# ecd5_target_db register map
Vendor: Texas Instruments
Address unit: 16 bits
Registers are 32-bit, access per field, reset 0x0 unless marked. A register's access mark holds for its fields unless they carry their own. Offsets are as the file gives them; [hi:lo] are bit positions; {n}, {i} and the like mark numbered series; 'fields as' and 'values as' point back to an identical list; <NAME> marks a mode.

## DSS (part 3 of 5) — ipxact12_to_ccs_generated
0x324 __ALL___DDR_BITSTRM_BASE_ADDR_SHADOW ro — DDR bitstream base address shadow
  [31:0] ADDR — Shadow base address of bit stream buffer in DDR
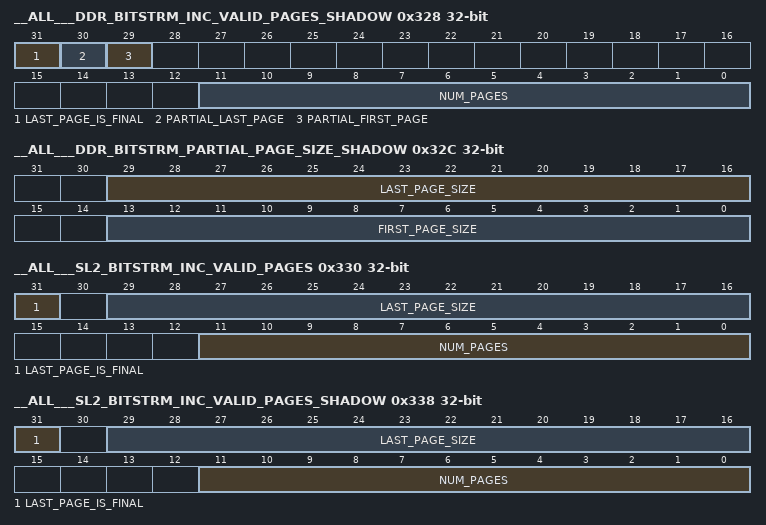
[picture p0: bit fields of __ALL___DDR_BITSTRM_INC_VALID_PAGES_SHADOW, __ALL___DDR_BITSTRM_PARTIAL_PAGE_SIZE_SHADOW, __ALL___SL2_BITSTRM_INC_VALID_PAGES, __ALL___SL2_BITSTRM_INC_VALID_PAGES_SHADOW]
0x328 __ALL___DDR_BITSTRM_INC_VALID_PAGES_SHADOW — DDR bitstream incremental valid pages shadow
  [31] LAST_PAGE_IS_FINAL rw — Shadow of flag indicating whether the last page in the current DDR data descriptor is the last in the DDR, i.e. no more data available in DDR after the last page in the current DDR data descriptor.
  [30] PARTIAL_LAST_PAGE rw — Shadow of flag indicating whether the last page in the current DDR data descriptor is a partial page, i.e. it is not of the full page size.
  [29] PARTIAL_FIRST_PAGE rw — Shadow of flag indicating whether the first page in the current DDR data descriptor is a partial page, i.e. it is not of the full page size. Note : This field is ignored if NUM_PAGES == 1 and PARTIAL_LAST_PAGE == 1.
  [11:0] NUM_PAGES rw — Shadow of the number of bitstream buffer pages that have been incrementally filled in DDR. This is also a working register field and gets decremented after completion of DMA transfer of each page between DDR and SL2
0x32C __ALL___DDR_BITSTRM_PARTIAL_PAGE_SIZE_SHADOW — DDR bitstream incremental valid pages shadow
  [29:16] LAST_PAGE_SIZE rw — Shadow of the size in bytes of the data in the last page. This field is valid only if the DDR_BITSTRM_INC_VALID_PAGES_SHADOW.PARTIAL_LAST_PAGE == 1
  [13:0] FIRST_PAGE_SIZE rw — Shadow of the size in bytes of the data in the last page. This field is valid only if the DDR_BITSTRM_INC_VALID_PAGES_SHADOW.PARTIAL_FIRST_PAGE == 1
0x330 __ALL___SL2_BITSTRM_INC_VALID_PAGES — SL2 bitstream incremental valid pages This register is used only in the fragmented mode
  [31] LAST_PAGE_IS_FINAL rw — Flag indicating whether the last page in the current SL2 data descriptor is the last available i.e. no more data available in SL2 after the last page in the current SL2 data descriptor
  [29:16] LAST_PAGE_SIZE rw — Indicates the size in bytes of the data in the last page. This field is valid only if LAST_PAGE_IS_FINAL == 1
  [11:0] NUM_PAGES rw — Number of bitstream buffer pages that have been incrementally filled in SL2 (in decode), or is available to be filled by the core (in encode)
0x334 __ALL___SL2_BITSTRM_SHADOW_STATUS ro — SL2 bitstream shadow status register This register is used only in the fragmented mode
  [0] INC_VALID_PAGES_UPDATED — Indicates if SL2_BITSTRM_INC_VALID_PAGES contents have been updated 1 : SL2_BITSTRM_INC_VALID_PAGES has been updated and contents have not yet been copied into the shadow register 0 : SL2_BITSTRM_INC_VALID_PAGES has not been updated, or contents have already been copied into the shadow register; SL2_BITSTRM_INC_VALID_PAGES can be written again
0x338 __ALL___SL2_BITSTRM_INC_VALID_PAGES_SHADOW ro — SL2 bitstream incremental valid pages shadow This register is used only in the fragmented mode
  [31] LAST_PAGE_IS_FINAL — Shadow of flag indicating whether the last page in the current SL2 data descriptor is the last available, i.e. no more data available in SL2 after the last page in the current SL2 data descriptor
  [29:16] LAST_PAGE_SIZE — Shadow of the size in bytes of the data in the last page. This field is valid only if LAST_PAGE_IS_FINAL == 1
  [11:0] NUM_PAGES — Shadow number of bitstream buffer pages that have been filled in SL2 (in decode), or available to be filled by the core (in encode); this field gets decremented after ECD5 (SBC) completes processing one page of bit-stream data
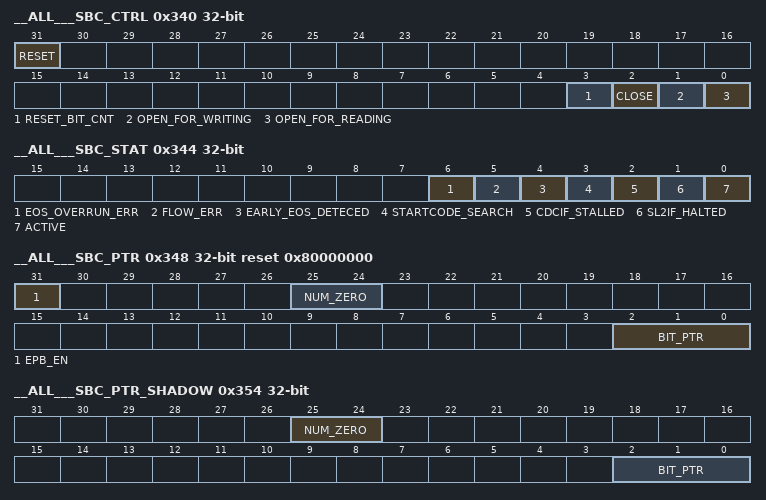
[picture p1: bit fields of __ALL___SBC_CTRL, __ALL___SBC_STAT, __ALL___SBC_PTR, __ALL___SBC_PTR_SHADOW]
0x340 __ALL___SBC_CTRL — SBC Control
  [31] RESET rw — Writing "1" resets SBC; for debug only
  [3] RESET_BIT_CNT rw — Writing "1" resets the bit counters in SBC; resets SBC_TOTAL_COUNT to 0; also resets internal counters; cleared in the next cycle.
  [2] CLOSE rw — Writing "1" closes SBC; automatically cleared on close completion
  [1] OPEN_FOR_WRITING rw — Writing "1" opens SBC for writing; automatically cleared on open completion
  [0] OPEN_FOR_READING rw — Writing "1" opens SBC for reading; automatically cleared on open completion
0x344 __ALL___SBC_STAT ro — SBC Status
  [6] EOS_OVERRUN_ERR — If 1, in decode, indicates that end of slice overrun happened; cleared on open completion.
  [5] FLOW_ERR — If 1, indicates that an underflow (decode) or overflow (encode) error is seen; cleared on open completion.
  [4] EARLY_EOS_DETECED — If 1, in decode, indicates that an early EOS was detected; cleared on open completion.
  [3] STARTCODE_SEARCH — If 1, indicates that startcode search is active; cleared automatically on startcode search completion.
  [2] CDCIF_STALLED — If 1, indicates that codec i/f of SBC is stalled (not ready), due to lack of data in the internal registers of the SBC; valid after open; cleared on codec i/f becoming unstalled.
  [1] SL2IF_HALTED — If 1, indicates that the SL2 i/f of SBC is halted, due to lack of bitstream data in the SL2; valid after open; cleared when SL2 i/f is unhalted
  [0] ACTIVE — If 1, indicates that SBC is active - can be in read/write or halted state; valid after open; cleared on close
0x348 __ALL___SBC_PTR reset 0x80000000 — SL2 bit pointer for SBC
  [31] EPB_EN rw — Enable EPB insertion (encode/write mode) or removal (decode/read mode)
  [25:24] NUM_ZERO rw — Number of zero bytes in the past. This is used for emulation prevention byte manipulation. The following constraint applies : 0 <= NUM_ZERO <= 2
  [2:0] BIT_PTR rw — Next bit position in the byte at BYTEPTR. The following constraint applies : 0 <= BITPTR <= 7
0x34C __ALL___SBC_TOTAL_COUNT — Number of bits read/written by the SBC - i.e. decoded/encoded by the codec
  [26:0] CNT rw — a. In decode, used to keep track of slice level bits decoded b. Additionally, in decode, if SBC_NALU_CFG.SIZE_CHK_EN==1, used to compare against the NALU size to detect bitstream underflow and early EOS c. In encode, used to keep track of slice level bits encoded d. Additionally, in H.241 encode, used to compare against the NALU_CFG.SIZE register to identify slice threshold exceeded condition, and thereby trigger rewind This counter is also incremented during start code searching. This bit count includes EPB. This register will have to be programmed before ECD is triggered for unit processing, to account for the bits decoded/encoded by iCont during header processing
0x350 __ALL___SBC_NALU_CFG — Total size of NALU in bytes
  [21:0] SIZE rw — In decode, specifies the total size of the NALU in bytes. This field is valid/used only if SIZE_CHK_EN == 1. In encode, in H.241 mode, specifies the slice limit
0x354 __ALL___SBC_PTR_SHADOW — SL2 bit pointer shadow for SBC
  [25:24] NUM_ZERO rw — Number of zero bytes in the past. This is used for emulation prevention byte manipulation. The following constraint applies : 0 <= NUM_ZERO <= 2
  [2:0] BIT_PTR rw — Next bit position in the byte at BYTEPTR. The following constraint applies : 0 <= BITPTR <= 7
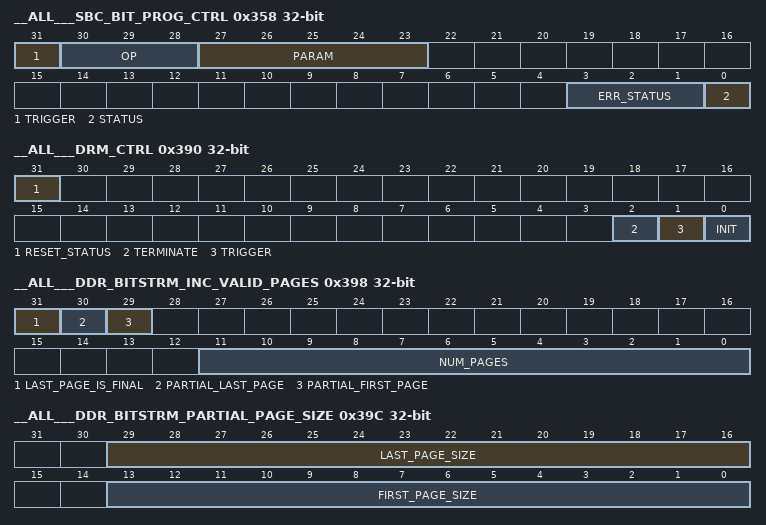
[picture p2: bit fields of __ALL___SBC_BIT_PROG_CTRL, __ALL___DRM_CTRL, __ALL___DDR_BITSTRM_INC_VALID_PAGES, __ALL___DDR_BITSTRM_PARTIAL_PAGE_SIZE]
0x358 __ALL___SBC_BIT_PROG_CTRL — SBC Bit Programmation Control Register
  [31] TRIGGER rw — Writing to this bit triggers the bit processing operation of the SBC. The operation performed depends on the "OP" field. This bit remains set until the specified operation completes, successfully or unsuccessfully
  [30:28] OP rw — Specified the bit manipulation operation to be performed 0x0 : Put bits; write specified (number and value) bits into SL2; increments bit pointer 0x1 : Jump bits; skip over specified number of bits in the SL2; increments the bit pointer 0x2 : Startcode search : do startcode search 0x3 : Get_num_bits_left_in_byte : get the number of bits needed to align the bit pointer to the beginning of the next byte 0x4 : Insert rbsp_trailing_bits; increments bit pointer
  [27:23] PARAM rw — Specifies the parametes for the requested bit processing operation. The meaning of this field depends on the operation requested. The mapping of the operation (OP field) to the meaning of this field is as follows: 0x0 (put bits) : number of bits to be put 0x1 (jump bits) : number of bits to be jumped over; the next 32 bits are then provided in SBC_BIT_PROG_DATA Valid values of this field are 0 to 31
  [3:1] ERR_STATUS rw — If STATUS == 0 when TRIGGER goes to 0, i.e. error was encountered during the specified operation, this field gives details on the error 0x0 : No error 0x1 : SBC not activated yet ( i.e. not opened) 0x2 : If OP == 0 or 1 or 4, SBC not ready; this happens when there is not sufficient bits (in case of decode) or space (in case of encode) to service the specified put_bits or jump_bits request If OP == 2, startcode was not found in the available data, 0x3 : If OP == 2, invalid operation due to startcode search triggered while the SBC was in write mode If OP == 4, invalid operation due to insertion of rbsp_trailing_bits triggered while the SBC was in read mode
  [0] STATUS rw — Indicates the completion status of the specified operation. This field is valid only when "TRIGGER" is 0. This field is cleared on setting TRIGGER to 1. A "1" in this field when TRIGGER goes to 0, indicates successful completion of the specified operation
0x35C __ALL___SBC_BIT_PROG_DATA rw — SBC Bit Programmation Data Register
  [31:0] DATA — If SBC_BIT_PROG_CTRL.OP == 0 (put bits), this register holds the data that needs to be written to SL2 through SBC If SBC_BIT_PROG_CTRL.OP == 1 (jump bits), this register holds the next 32 bit data read from SL2 through SBC, after jumping by the specified length If SBC_BIT_PROG_CTRL.OP == 3 (get bits left in byte), this register holds the number of bits left in the current byte, to align to the next byte boundary
0x390 __ALL___DRM_CTRL — DRM Control for bitstream
  [31] RESET_STATUS rw — Reset the status bits in DDR_BITSTRM_SHADOW_STATUS and SL2_BITSTRM_SHADOW_STATUS; Cleared in the next cycle
  [2] TERMINATE rw — Debug only. Terminate DMA transfers; if set, then the following actions take place - All in-flight DMA is completed - If DMA direction is from SL2 to DDR, all pending DMA requests are completed - If DMA direction is from DDR to SL2, all pending DMA requests are discarded. - Status bits in DDR_BITSTRM_SHADOW_STATUS register are reset
  [1] TRIGGER rw — Debug only. SW trigger; used to indicate consumption on 1 page in the buffer. Setting this bit will trigger a VDMA request.
  [0] INIT rw — Initializes the bitstream DRM FSM. This bit can be set to start the bit stream DMA through SW programming only, without involving the ECD5 controller logic.
0x394 __ALL___DDR_BITSTRM_BASE_ADDR rw — DDR bitstream base address
  [31:0] DDR_BITSTRM_BASE_ADDR — Base address of bit stream buffer in DDR
0x398 __ALL___DDR_BITSTRM_INC_VALID_PAGES — DDR bitstream incremental valid pages
  [31] LAST_PAGE_IS_FINAL rw — Flag indicating whether the last page in the current DDR data descriptor is the last in the DDR, i.e. no more data available in DDR after the last page in the current DDR data descriptor. The DRM's VDMA i/f will terminate after the transfer of the last page in the current descriptor, if this flag is set. Any descriptors already programmed after the current descriptor will remain unused.
  [30] PARTIAL_LAST_PAGE rw — Flag indicating whether the last page in the current DDR data descriptor is a partial page, i.e. it is not of the full page size. The size of the partial page is specified in DDR_BITSTRM_PARTIAL_PAGE_SIZE.LAST_PAGE_SIZE. Data transferred to/from the SL2 will be aligned to the top of the SL2 page, i.e. DDR_BITSTRM_PARTIAL_PAGE_SIZE.LAST_PAGE_SIZE amount of data will be transferred to/from the top of the current SL2 page.
  [29] PARTIAL_FIRST_PAGE rw — Flag indicating whether the first page in the current DDR data descriptor is a partial page, i.e. it is not of the full page size. The size of the partial page is specified in DDR_BITSTRM_PARTIAL_PAGE_SIZE.FIRST_PAGE_SIZE. Data transferred to/from the SL2 will be aligned to the bottom of the SL2 page, i.e. DDR_BITSTRM_PARTIAL_PAGE_SIZE.FIRST_PAGE_SIZE amount of data will be transferred to/from the bottom of the current SL2 page. Note : This field is ignored if NUM_PAGES == 1 and PARTIAL_LAST_PAGE == 1.
  [11:0] NUM_PAGES rw — Number of bitstream buffer pages that have been incrementally filled in DDR. Setting this field to 0 force terminates the DRM's VDMA i/f (forces DRM VDMA i/f FSM to IDLE state, clears the fields of DDR_BITSTRM_SHADOW_STATUS) after completion of all previous data transfers specified by any previous bit stream descriptor. If there are no data transfers pending, setting this field to 0 force terminates the DRM immediately. Additionally, setting this bit causes the DRM to signal the last page of the previous bitstream descriptor as last, to the SBC. Note : If PARTIAL_FIRST_PAGE == PARTIAL_LAST_PAGE == 1, then NUM_PAGES has to be greater than 2.
0x39C __ALL___DDR_BITSTRM_PARTIAL_PAGE_SIZE — DDR bitstream incremental valid pages
  [29:16] LAST_PAGE_SIZE rw — Indicates the size in bytes of the data in the last page. This field is valid only if the DDR_BITSTRM_INC_VALID_PAGES.PARTIAL_LAST_PAGE == 1
  [13:0] FIRST_PAGE_SIZE rw — Indicates the size in bytes of the data in the last page. This field is valid only if the DDR_BITSTRM_INC_VALID_PAGES.PARTIAL_FIRST_PAGE == 1
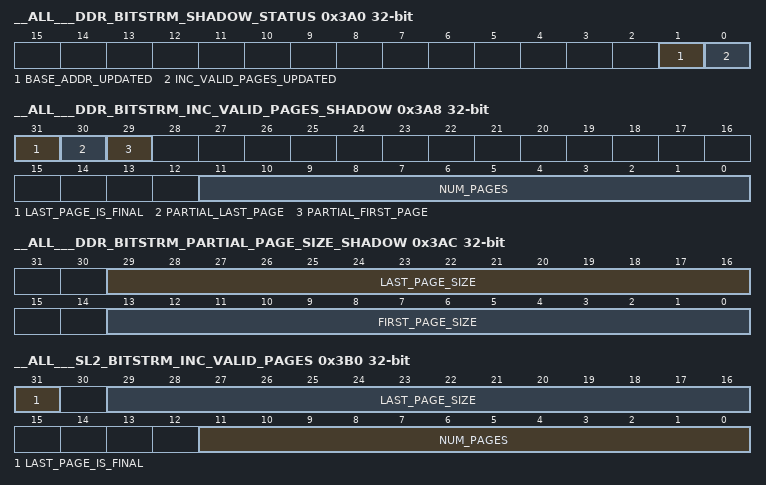
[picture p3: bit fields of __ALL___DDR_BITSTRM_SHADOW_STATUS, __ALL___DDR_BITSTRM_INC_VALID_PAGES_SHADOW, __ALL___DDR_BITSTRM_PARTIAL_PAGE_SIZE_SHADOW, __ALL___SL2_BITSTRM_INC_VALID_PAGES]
0x3A0 __ALL___DDR_BITSTRM_SHADOW_STATUS ro — DDR bitstream shadow status register
  [1] BASE_ADDR_UPDATED — Indicates if DDR_BITSTRM_BASE_ADDR contents have been updated 1 : DDR_BITSTRM_BASE_ADDR has been updated and contents have not yet been copied into the shadow register 0 : DDR_BITSTRM_BASE_ADDR has not been updated, or contents have already been copied into the shadow register; DDR_BITSTRM_BASE_ADDR can be written again
  [0] INC_VALID_PAGES_UPDATED — Indicates if DDR_BITSTRM_INC_VALID_PAGES contents have been updated 1 : DDR_BITSTRM_INC_VALID_PAGES has been updated and contents have not yet been copied into the shadow register 0 : DDR_BITSTRM_INC_VALID_PAGES has not been updated, or contents have already been copied into the shadow register; DDR_BITSTRM_INC_VALID_PAGES can be written again
0x3A4 __ALL___DDR_BITSTRM_BASE_ADDR_SHADOW ro — DDR bitstream base address shadow
  [31:0] DDR_BITSTRM_BASE_ADDR_SHADOW — Shadow base address of bit stream buffer in DDR
0x3A8 __ALL___DDR_BITSTRM_INC_VALID_PAGES_SHADOW — DDR bitstream incremental valid pages shadow
  fields as __ALL___DDR_BITSTRM_INC_VALID_PAGES_SHADOW
0x3AC __ALL___DDR_BITSTRM_PARTIAL_PAGE_SIZE_SHADOW — DDR bitstream incremental valid pages shadow
  fields as __ALL___DDR_BITSTRM_PARTIAL_PAGE_SIZE_SHADOW
0x3B0 __ALL___SL2_BITSTRM_INC_VALID_PAGES — SL2 bitstream incremental valid pages This register is used only in the fragmented mode
  fields as __ALL___SL2_BITSTRM_INC_VALID_PAGES
0x3B4 __ALL___SL2_BITSTRM_SHADOW_STATUS ro — SL2 bitstream shadow status register This register is used only in the fragmented mode
  fields as __ALL___SL2_BITSTRM_SHADOW_STATUS
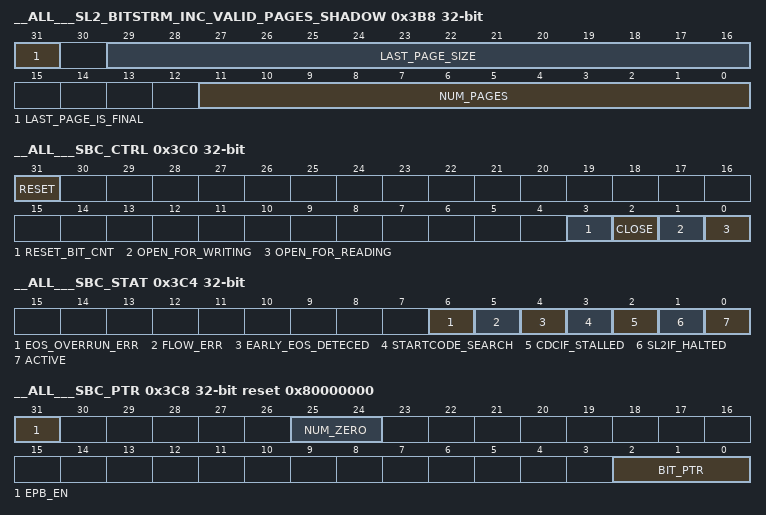
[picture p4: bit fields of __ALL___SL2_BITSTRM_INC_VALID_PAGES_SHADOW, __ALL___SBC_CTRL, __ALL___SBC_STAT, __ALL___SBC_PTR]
0x3B8 __ALL___SL2_BITSTRM_INC_VALID_PAGES_SHADOW ro — SL2 bitstream incremental valid pages shadow This register is used only in the fragmented mode
  fields as __ALL___SL2_BITSTRM_INC_VALID_PAGES_SHADOW
0x3C0 __ALL___SBC_CTRL — SBC Control
  fields as __ALL___SBC_CTRL
0x3C4 __ALL___SBC_STAT ro — SBC Status
  fields as __ALL___SBC_STAT
0x3C8 __ALL___SBC_PTR reset 0x80000000 — SL2 bit pointer for SBC
  fields as __ALL___SBC_PTR
0x3CC __ALL___SBC_TOTAL_COUNT — Number of bits read/written by the SBC - i.e. decoded/encoded by the codec
  fields as __ALL___SBC_TOTAL_COUNT
0x3D0 __ALL___SBC_NALU_CFG — Total size of NALU in bytes
  fields as __ALL___SBC_NALU_CFG
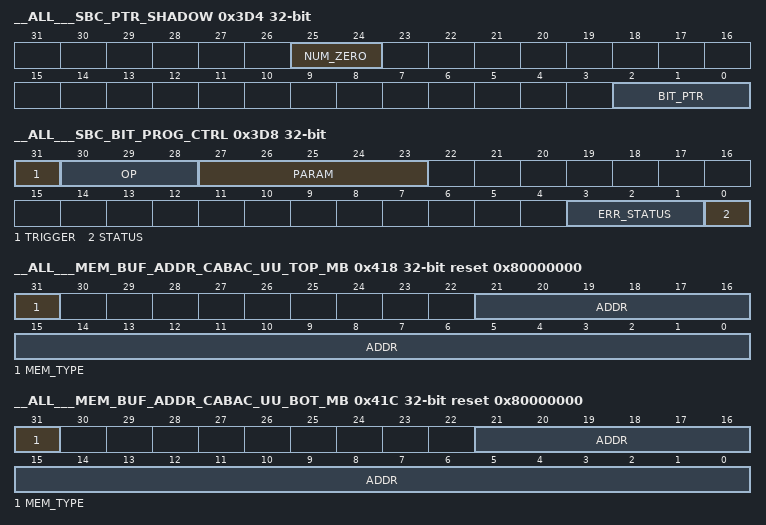
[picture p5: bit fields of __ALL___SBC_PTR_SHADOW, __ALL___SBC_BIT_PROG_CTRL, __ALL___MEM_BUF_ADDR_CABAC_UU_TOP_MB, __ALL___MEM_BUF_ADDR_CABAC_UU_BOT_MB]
0x3D4 __ALL___SBC_PTR_SHADOW — SL2 bit pointer shadow for SBC
  fields as __ALL___SBC_PTR_SHADOW
0x3D8 __ALL___SBC_BIT_PROG_CTRL — SBC Bit Programmation Control Register
  fields as __ALL___SBC_BIT_PROG_CTRL
0x3DC __ALL___SBC_BIT_PROG_DATA rw — SBC Bit Programmation Data Register
  fields as __ALL___SBC_BIT_PROG_DATA
0x400 __ALL___SL2_BUF_ADDR_SLICEINFO — sliceInfo SL2 Buffer Base Address
  [21:0] ADDR rw — Base Address of sliceInfo in SL2 (128 bit aligned); bits[3:0] hardwired to 0
0x404 __ALL___SL2_BUF_ADDR_BITSTRM — Bitstream SL2 Buffer Base Address
  [21:0] ADDR rw — Base address of bit stream buffer in SL2 (128 bit aligned); bits[3:0] hardwired to 0
{0x408+4i} __ALL___SL2_BUF_ADDR_BIN{i} (i=0..3) — Bin Stream {i} SL2 Buffer base address
  [21:0] ADDR rw — Base Address of Bin stream {i} in SL2 (128 bit aligned); bits[3:0] hardwired to 0
0x418 __ALL___MEM_BUF_ADDR_CABAC_UU_TOP_MB reset 0x80000000 — Upper Top MB Buffer Base Address for CABAC neighouring MB data in internal memory or SL2
  [31] MEM_TYPE rw — Specifies whether buffer is in SL2 or internal memory 0 : SL2, 1 : Internal memory
  [21:0] ADDR rw — Base Address for Upper MB Row, Top MB in the Pair If MEM_TYPE == 0, address in SL2 (128 bit aligned) specified; bits[3:0] hardwired to 0 If MEM_TYPE == 1, address in internal memory (128 bit aligned) specified;bits[3:0] hardwired to 0; bits [22:15] unused.
0x41C __ALL___MEM_BUF_ADDR_CABAC_UU_BOT_MB reset 0x80000000 — Upper Top MB Buffer Base Address for CABAC neighouring MB data in internal memory or SL2
  [31] MEM_TYPE rw — Specifies whether buffer is in SL2 or internal memory 0 : SL2, 1 : Internal memory
  [21:0] ADDR rw — Base Address for Upper MB Row, Bottom MB in the Pair If MEM_TYPE == 0, address in SL2 (128 bit aligned) specified; bits[3:0] hardwired to 0 If MEM_TYPE == 1, address in internal memory (128 bit aligned) specified;bits[3:0] hardwired to 0; bits [22:15] unused.
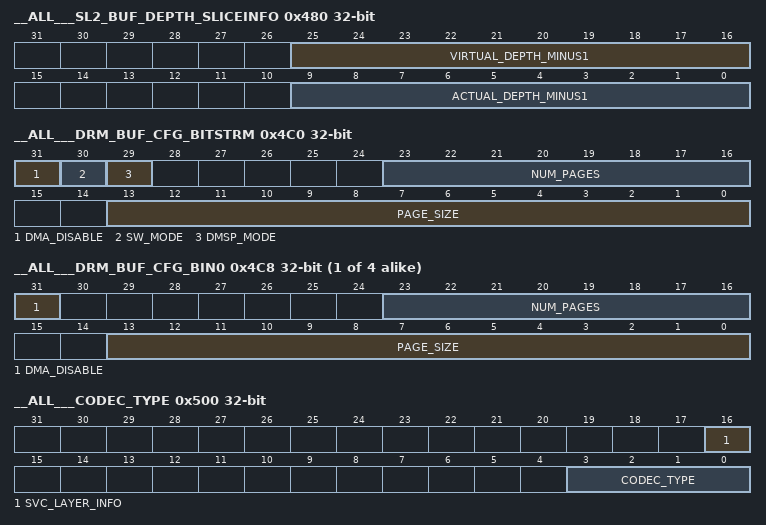
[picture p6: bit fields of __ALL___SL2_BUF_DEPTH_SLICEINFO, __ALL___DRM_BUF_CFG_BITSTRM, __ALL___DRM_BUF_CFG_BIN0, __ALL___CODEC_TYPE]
0x480 __ALL___SL2_BUF_DEPTH_SLICEINFO — Buffer Control Parameters for sliceInfo Buffer Note : This register is used by the FE for handling the SL2BC to the BE and ROP as well as for describing the input sliceInfo buffer to FE.
  [25:16] VIRTUAL_DEPTH_MINUS1 rw — BC Virtual Depth
  [9:0] ACTUAL_DEPTH_MINUS1 rw — BC Actual Depth
0x484 __ALL___SL2_BUF_START_PTR_SLICEINFO — Buffer Control Pointers for sliceInfo Buffer (to BE + ROP) Note : This register is used by the FE for handling the SL2BC to the BE and ROP as well as for describing the input sliceInfo buffer to FE.
  [9:0] START_PTR rw — BC Start Value for Write Pointer. Also used as the start value for reading the sliceInfo buffer by the FE.
0x488 __ALL___SL2_BUF_PTR_INC_SLICEINFO reset 0x1 — Buffer Control Pointer Increment Parameters for sliceInfo buffer (to BE + ROP) Note : This register is used by the FE for handling the SL2BC to the BE and ROP as well as for describing the input sliceInfo buffer to FE.
  [9:0] PTR_INC rw — BC Increment value for Write pointer. Also used as the increment value for the read pointer for reading sliceInfo buffer by FE.
0x48C __ALL___SL2_BUF_DEPTH_MB — Buffer Control Parameters for MB decoupling between FE and BE Note : Valid only in N MB decoupled mode
  [9:0] ACTUAL_DEPTH_MINUS1 rw — BC Actual Depth
{0x498+8i} __ALL___SL2_BUF_DEPTH_BIN{i} (i=0..3) — Buffer Control Parameters for bin stream {i} Note : Valid only in N MB decoupled mode
  [15:0] ACTUAL_DEPTH_MINUS1 rw — BC Actual Depth
{0x49C+8i} __ALL___SL2_BUF_START_PTR_BIN{i} rw (i=0..3) — Buffer Control Pointers for bin stream {i} Note : Valid only in N MB decoupled mode
  [15:0] WRITE_START_PTR — BC Start Value for Write Pointer
0x4C0 __ALL___DRM_BUF_CFG_BITSTRM — Buffer parameters and configuration for bit stream Note : In the non-frame decoupled configuration, this register is used for DRM configuration. The corresponding registers in BE are unused
  [31] DMA_DISABLE rw — If '1', disables the triggering of VDMA. Only the SL2 buffer management is activated.
  [30] SW_MODE rw — If '1', specifies SW interactive mode of operation. In this mode, the ECD5 does not interact directly with VDMA for bitstream DMA. Instead it triggers an interrupt for requesting DMA transfer of bitstream.
  [29] DMSP_MODE rw — If '1', specifies "Direct Multi-page SL2 population" mode of operation
  [23:16] NUM_PAGES rw — Number of pages in SL2
  [13:0] PAGE_SIZE rw — Size of each page in SL2 (in bytes); bits[3:0] are ignored, so the effective size is a multiple of 16 bytes
0x4C4 __ALL___DRM_BUF_DMAGROUPID_BITSTRM — DMA Group ID for bit stream Note : In the non-frame decoupled configuration, this register is used for DRM configuration. The corresponding registers in BE are unused
  [5:0] ID rw — Group ID for VDMA transfer
{0x4C8+8i} __ALL___DRM_BUF_CFG_BIN{i} (i=0..3) — Buffer Parameters and configuration for bin stream {i} Note : Valid only in frame decoupled mode
  [31] DMA_DISABLE rw — If '1', disables the triggering of VDMA. Only the SL2 buffer management is activated.
  [23:16] NUM_PAGES rw — Number of pages in SL2
  [13:0] PAGE_SIZE rw — Size of each page in SL2 (in bytes); bits[3:0] are ignored, so the effective size is a multiple of 16 bytes Although the VDMA transfer for bin stream is deterministic, PAGE_SIZE is needed by ECD5 to know when to trigger VDMA - i.e. when the page becomes full. Since the size of each entry/write in the bin buffer is not fixed, the DMA is triggered when the total size of the wriiten data reaches PAGE_SIZE
{0x4CC+8i} __ALL___DRM_BUF_DMAGROUPID_BIN{i} (i=0..3) — DMA Group ID for bin stream {i} Note : Valid only in frame decoupled mode
  [5:0] ID rw — Group ID for VDMA transfer
0x500 __ALL___CODEC_TYPE — ECD5 Codec Type
  [16] SVC_LAYER_INFO rw — Specifies whether current layer is base or enhancement layer; valid only id CODEC_TYPE == 1 (SVC) 0 - Base Layer 1 - Enhancement Layer
  [3:0] CODEC_TYPE rw — 0=>H.264, 1=>SVC, 2=>VP8
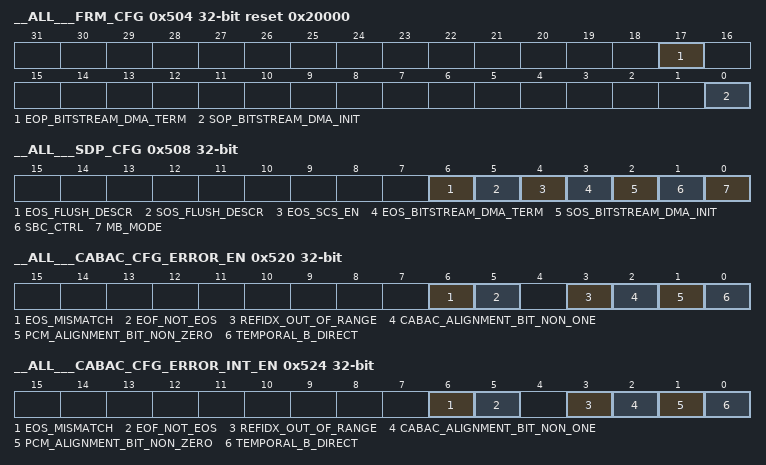
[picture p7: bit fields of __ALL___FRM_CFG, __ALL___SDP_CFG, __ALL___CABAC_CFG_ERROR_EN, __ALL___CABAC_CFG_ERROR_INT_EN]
0x504 __ALL___FRM_CFG reset 0x20000 — FE Frame Level Initialization Control
  [17] EOP_BITSTREAM_DMA_TERM rw — Specifies if bit-stream DMA needs to be terminated at the end of pipe (frame/sub-frame) 0 - Do not terminate bit stream DMA at the end of pipe 1 - Terminate bitstream DMA at end of pipe
  [0] SOP_BITSTREAM_DMA_INIT rw — Specifies if bit-stream DMA needs to be initialized at the start of pipe (frame/sub-frame) 0 - Disable 1 - Enable
0x508 __ALL___SDP_CFG — FE Slice Data Processing Configuration register
  [6] EOS_FLUSH_DESCR rw — Enable/Disable flush of current bitstream descriptor at end of slice 0 - Disable 1 - Enable
  [5] SOS_FLUSH_DESCR rw — Enable/Disable flush of current bitstream descriptor at start of slice 0 - Disable 1 - Enable
  [4] EOS_SCS_EN rw — Enable/Disable automatic startcode search on detecting end of slice 0 - Disable 1 - Enable
  [3] EOS_BITSTREAM_DMA_TERM rw — Specifies if bit-stream DMA needs to be terminated at the end of slice 0 - Do not terminate bit stream DMA at the end of slice 1 - Terminate bitstream DMA at end of slice
  [2] SOS_BITSTREAM_DMA_INIT rw — Specifies if bit-stream DMA need to be init at beginning of slice data processing 0 - Do not trigger initial bit stream DMA at the beginning of slice 1 - Trigger bitstream DMA at beginning of every slice
  [1] SBC_CTRL rw — Specifies the SBC control mode 0 - Initialize and Flush SBC at beginning and end of slice respectively 1 - Initialize and Flush SBC at beginning and end of every MB respectively Note : If SDP_EOS_SCS_EN == 1, then this bit will take effect for SBC close after the startcode search after EOS.
  [0] MB_MODE rw — Specifies if MB mode is enabled for slice data decode 0 - No control at MB level 1 - MB processing engine has to be specifically enabled at every MB
0x520 __ALL___CABAC_CFG_ERROR_EN — CABAC Configuration register for enabling error for potentially incorrect behavior
  [6] EOS_MISMATCH rw — If this value is 1 and EOS mismatch is detected, error is flagged immediately. EOS mismatch is detected when a. EOS flag in MB is "1", but there is more data in the bit-stream b. EOS flag in MB is "0", but there is no more data in the bit-stream
  [5] EOF_NOT_EOS rw — If this value is 1 and EOS is not detected while decoding the last MB in the frame, error is flagged immediately.
  [3] REFIDX_OUT_OF_RANGE rw — If this value is 1 and ref_idx_lx ( x == 0 or 1 ) is out of the range [0,CABAC_REF_IDX_MAX_Lx.VALUE], error is flagged immediately .
  [2] CABAC_ALIGNMENT_BIT_NON_ONE rw — If this value is 1 and cabac_alignment_one_bit is not "1", error is flagged immediately.
  [1] PCM_ALIGNMENT_BIT_NON_ZERO rw — If this value is 1 and pcm_alignment_zero_bit is not "0", error is flagged immediately.
  [0] TEMPORAL_B_DIRECT rw — If this value is 1 and Temporal B Direct MB is detected, error is flagged immediately.
0x524 __ALL___CABAC_CFG_ERROR_INT_EN — CABAC Configuration register for enabling interrupt for potentially incorrect behavior If a bit is set in this register and corresponding bit is not set in the CABAC_CFG_ERROR_EN register, then, on hitting the corresponding condition in an MB, INT_ERR1 is triggered on the completion of the MB. CABAC_DEC_ERR status bit is set in the interrupt status registers corresponding to INT_ERR1.
  [6] EOS_MISMATCH rw — If this value is 1 and EOS mismatch is detected, interrupt is (conditionally) generated on completion of MB EOS mismatch is detected when a. EOS flag in MB is "1", but there is more data in the bit-stream b. EOS flag in MB is "0", but there is no more data in the bit-stream
  [5] EOF_NOT_EOS rw — If this value is 1 and EOS is not detected while decoding the last MB in the frame, interrupt is (conditionally) generated on completion of MB.
  [3] REFIDX_OUT_OF_RANGE rw — If this value is 1 and ref_idx_lx (x == 0 or 1 ) is out of the range [0,CABAC_REF_IDX_MAX_Lx.VALUE], interrupt is (conditionally) generated on completion of MB.
  [2] CABAC_ALIGNMENT_BIT_NON_ONE rw — If this value is 1 and cabac_alignment_one_bit is not "1", interrupt is (conditionally) generated on completion of MB.
  [1] PCM_ALIGNMENT_BIT_NON_ZERO rw — If this value is 1 and pcm_alignment_zero_bit is not "0", interrupt is (conditionally) generated on completion of MB.
  [0] TEMPORAL_B_DIRECT rw — If this value is 1 and Temporal B Direct MB is detected, interrupt is (conditionally) generated on completion of MB.
0x528 __ALL___CABAC_REF_IDX_MAX_L0 — CABAC Max refidx for L0
  [4:0] VALUE rw — Specifies the max refidx value for L0 for error checking
0x52C __ALL___CABAC_REF_IDX_MAX_L1 — CABAC Max refidx for L1
  [4:0] VALUE rw — Specifies the max refidx value for L1 for error checking
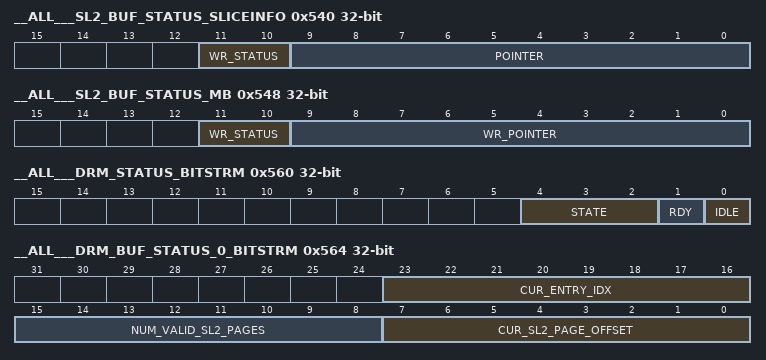
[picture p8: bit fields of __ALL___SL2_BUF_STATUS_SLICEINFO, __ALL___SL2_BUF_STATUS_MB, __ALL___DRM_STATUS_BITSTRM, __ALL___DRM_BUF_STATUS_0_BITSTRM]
0x540 __ALL___SL2_BUF_STATUS_SLICEINFO ro — Buffer Status for sliceInfo Note : Valid only in N MB decoupled mode
  [11:10] WR_STATUS — Indicates the BC status on the write side BC NOT READY = 00 (wr_core_busy=0 AND wr_bc_ready=0) BC READY = 01 (wr_core_busy=0 AND wr_bc_ready=1) BC BUSY = 1x (wr_core_busy=1) Note : Valid only in N MB decoupled mode
  [9:0] POINTER — Current Pointer from where the sliceInfo will be read. This also points to the location from where the BE/ROP will read the sliceInfo , and therefore is the pointer to location virtually written by the FE, for consumption by the BE/ROP
0x548 __ALL___SL2_BUF_STATUS_MB ro — Buffer Status for MB decoupling between FE and BE Note : Valid only in N MB decoupled mode
  [11:10] WR_STATUS — Indicates the BC status on the write side BC NOT READY = 00 (wr_core_busy=0 AND wr_bc_ready=0) BC READY = 01 (wr_core_busy=0 AND wr_bc_ready=1) BC BUSY = 1x (wr_core_busy=1) Note : Valid only in N MB decoupled mode
  [9:0] WR_POINTER — Current Write Pointer
{0x54C+4i} __ALL___SL2_BUF_STATUS_BIN{i} ro (i=0..3) — Buffer Status for bin stream {i} Note : Valid only in N MB decoupled mode
  [15:0] WR_POINTER — Current Write Pointer
0x560 __ALL___DRM_STATUS_BITSTRM ro — Status of DRM channel controller for bit stream buffer
  [4:2] STATE — Indicates state of the bitstream control DRM FSM
  [1] RDY — Indicates availability of at least one valid page in SL2 for processing by the ECD core
  [0] IDLE — If "1", indicates that the DRM channel for bitstream control is IDLE. Used to check for completion of DMA after a terminate request.
0x564 __ALL___DRM_BUF_STATUS_0_BITSTRM ro — Buffer Status for bitstream buffer Reflects the current internal and DMA status of bit stream buffer
  [23:16] CUR_ENTRY_IDX — Unused
  [15:8] NUM_VALID_SL2_PAGES — Indicates the number of pages currently valid in SL2. In the case of read ( data transferred from DDR to SL2 , and read by the ECD core ), this field indicates the number of pages available for the ECD to read from SL2. This count is initialized to 0 on DRM initialization. This count is incremented on completion of each page of DMA. The count is decremented whenever one page of data is consumed by the ECD core. In the case of write ( data written by ECD core to SL2, and transferred from SL2 to DDR ), this field indicates the number of pages in SL2 available for the ECD core to write into. This count is initialized to the total number of pages (ECD5_BE_BUFFER_CONTROL.DRM_BUF_CFG_[BUFFER_NAME].NUM_PAGES) on DRM initialization. The count is decremented every time ECD writes one page to SL2. The count is incremented whenever the DMA of one page from SL2 to DDR is completed.
  [7:0] CUR_SL2_PAGE_OFFSET — Indicates the SL2 page number where the next data will be read from, by the ECD core (MBP); valid values are 0 to DRM_BUF_PARAMS_[BUFFER_NAME].NUM_PAGES - 1; reset on DMA initialization
0x568 __ALL___DRM_BUF_STATUS_1_BITSTRM ro — Buffer Status for bit stream buffer Reflects the current internal and DMA status of bit stream buffer
  [21:0] CUR_SL2_ADDR — Indicates the SL2 address of the page where the next data will be read from, by the ECD core (MBP) ; reset on DMA initialization to SL2 base address of the buffer in SL2
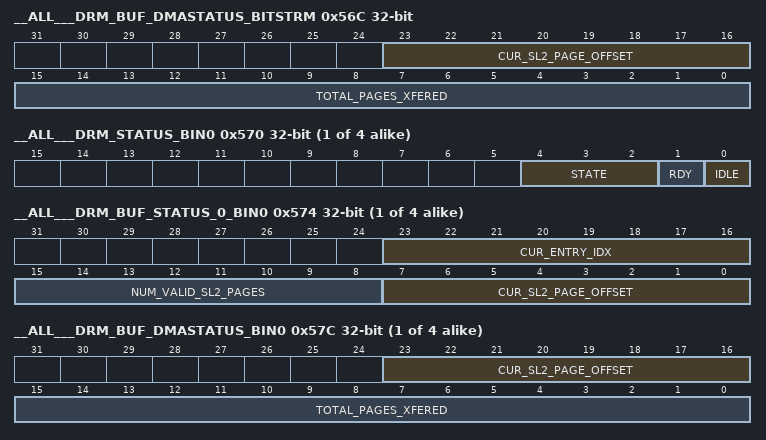
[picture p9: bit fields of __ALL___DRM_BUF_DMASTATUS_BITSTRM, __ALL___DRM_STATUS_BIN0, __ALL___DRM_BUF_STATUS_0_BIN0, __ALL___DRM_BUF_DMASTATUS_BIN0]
0x56C __ALL___DRM_BUF_DMASTATUS_BITSTRM ro — Buffer DMA Status for bitstream buffer Reflects the current DMA status of bin stream 0 buffer
  [23:16] CUR_SL2_PAGE_OFFSET — Indicates the SL2 page number to which the next page DMA will happen (written to) when enabling conditions for DMA are met (SL2 page is consumed by ECD5 core); valid values are 0 to DRM_BUF_PARAMS_[BUFFER_NAME].NUM_PAGES - 1; reset on DMA initialization
  [15:0] TOTAL_PAGES_XFERED — Indicates the total number of pages for which DMA has completed; reset on DMA initialization
{0x570+0x10*i} __ALL___DRM_STATUS_BIN{i} ro (i=0..3) — Status of DRM channel controller for bin stream {i} buffer
  [4:2] STATE — Indicates state of the channel control DRM FSM
  [1] RDY — Indicates availability of at least one valid page in SL2 for processing by the ECD core
  [0] IDLE — If "1", indicates that the DRM channel control FSM is IDLE. Used to check for completion of DMA after a terminate request.
{0x574+0x10*i} __ALL___DRM_BUF_STATUS_0_BIN{i} ro (i=0..3) — Buffer Status for bin stream {i} buffer Valid only in frame decoupled mode Reflects the current internal and DMA status of bin stream {i} buffer
  [23:16] CUR_ENTRY_IDX — Unused
  [15:8] NUM_VALID_SL2_PAGES — Indicates the number of pages currently valid in SL2. This field indicates the number of pages in SL2 available for the ECD core to write into. This count is initialized to the total number of pages (ECD5_BE_BUFFER_CONTROL.DRM_BUF_CFG_[BUFFER_NAME].NUM_PAGES) on DRM initialization. The count is decremented every time ECD writes one page to SL2. The count is incremented whenever the DMA of one page from SL2 to DDR is completed.
  [7:0] CUR_SL2_PAGE_OFFSET — Indicates the SL2 page number where the next data will be written to by the ECD core (MBP); valid values are 0 to DRM_BUF_PARAMS_[BUFFER_NAME].NUM_PAGES - 1; reset on DMA initialization
{0x578+0x10*i} __ALL___DRM_BUF_STATUS_1_BIN{i} ro (i=0..3) — Buffer Status for bin stream {i} buffer Valid only in frame decoupled mode. Reflects the current internal and DMA status of bin stream {i} buffer
  [21:0] CUR_SL2_ADDR — Indicates the SL2 address of the page where the next data will be written to, by the ECD core (MBP) ; reset on DMA initialization to SL2 base address of the buffer in SL2
{0x57C+0x10*i} __ALL___DRM_BUF_DMASTATUS_BIN{i} ro (i=0..3) — Buffer DMA Status for bin stream {i} buffer Valid only in frame decoupled mode. Reflects the current DMA status of bin stream {i} buffer
  [23:16] CUR_SL2_PAGE_OFFSET — Indicates the SL2 page number from which the next page DMA will happen (read from), when enabling conditions for DMA are met (SL2 page is filled by ECD5 core); valid values are 0 to DRM_BUF_PARAMS_[BUFFER_NAME].NUM_PAGES - 1; reset on DMA initialization
  [15:0] TOTAL_PAGES_XFERED — Indicates the total number of pages for which DMA has completed; reset on DMA initialization
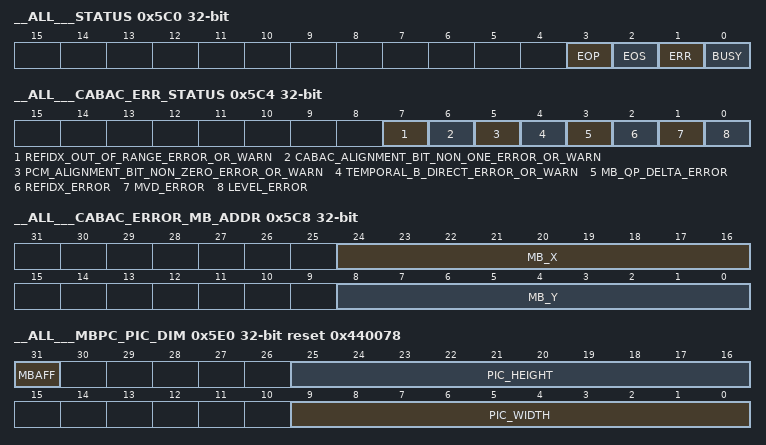
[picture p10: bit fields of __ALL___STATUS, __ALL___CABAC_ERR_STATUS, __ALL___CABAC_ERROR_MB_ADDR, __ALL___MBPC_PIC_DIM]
0x5C0 __ALL___STATUS ro — Current status
  [3] EOP — Indicates End of Pipe (frame/sub-frame) was detected during decode of the last Macroblock. If set to 1, indicates that the last macroblock is at the end of the frame/sub-frame. On detecting EOP, ECD5 issues EOP interrupt (if enabled) and sets this flag. EOP flag is automatically cleared by ECD5 core if one of the following condition is true: • EN bit in SYSTEM_MMR.ECD5_FE_ENABLE register is set to 1 * hwa_init request is received
  [2] EOS — Indicates End of Slice was detected during decode of the last Macroblock. If set to 1, indicates that the last macroblock is at the end of the slice. On detecting EOS, ECD5 issues EOS interrupt (if enabled) and sets this flag. EOS flag is automatically cleared by ECD5 core if either one of the following condition is true: • EN bit in SYSTEM_MMR.ECD5_FE_UNIT_ENABLE register is set to 1 • EN bit in SYSTEM_MMR.ECD5_FE_ENABLE register is set to 1 * hwa_init request is received
  [1] ERR — Indicates Error was detected during decode of last Macroblock. If set to 1, indicates that the last macroblock had error. On detecting error, ECD5 issues ERR interrupt (if enabled) and sets this flag. ERR flag is automatically cleared by ECD5 core if either one of the following condition is true: • EN bit in SYSTEM_MMR.ECD5_FE_UNIT_ENABLE register is set to 1 • EN bit in SYSTEM_MMR.ECD5_FE_ENABLE register is set to 1 * start of new macroblock processing * hwa_init request is received
  [0] BUSY — Indicates whether the FE-MBP is busy 0 - Idle 1 - Busy
0x5C4 __ALL___CABAC_ERR_STATUS — CABAC Error Status. This register reflects the status of any error detected during MB decode.
  [7] REFIDX_OUT_OF_RANGE_ERROR_OR_WARN rw — This bit is set if ref_idx_lx ( x == 0 or 1 ) out of the range [0,ECD5_FE_FUNC.CABAC_REF_IDX_MAX_LX.VALUE] is detected
  [6] CABAC_ALIGNMENT_BIT_NON_ONE_ERROR_OR_WARN rw — This bit is set if cabac_alignment_one_bit that is not "1" is detected
  [5] PCM_ALIGNMENT_BIT_NON_ZERO_ERROR_OR_WARN rw — This bit is set if pcm_alignment_zero_bit that is not "0" is detected
  [4] TEMPORAL_B_DIRECT_ERROR_OR_WARN rw — This bit is set if Temporal B Direct MB is detected.
  [3] MB_QP_DELTA_ERROR rw — This bit is set if decoded mb_qp_delta is out of range. Valid range of mb_qp_delta is as follows: [-26,25] when bitDepth == 8, [-20,31] when bitDepth == 10, [-14,37] when bitDepth == 12.
  [2] REFIDX_ERROR rw — This bit is set if decoded ref_idx_l0 or ref_idx_l1 is greater than 31.
  [1] MVD_ERROR rw — This bit is set if decoded MVD is out of range. Valid range of MVD is different between horizontal and vertical (Horizontal and vertical MVD have different out of range detectors) Valid Horizontal MVD range is [-16383,16383] in quarter-pel. Valid Vertical MVD range is [-4095,4095] in quarter-pel.
  [0] LEVEL_ERROR rw — This bit is set if level is out of range, this error is issued. Valid range of level is [-2^(7+bitDepth), 2^(7+bitDepth)-1].
0x5C8 __ALL___CABAC_ERROR_MB_ADDR ro — Error MB address This register provides the address of the MB in which error was detected in CABAC decode
  [24:16] MB_X — Specifies the X position of the error MB
  [8:0] MB_Y — Specifies the Y position of the error MB
0x5E0 __ALL___MBPC_PIC_DIM rw reset 0x440078 — FE MBPC Picture Dimensions
  [31] MBAFF — If "1", current picture is MBAFF
  [25:16] PIC_HEIGHT — PictureHeight in MBs
  [9:0] PIC_WIDTH — Picture Width in MBs
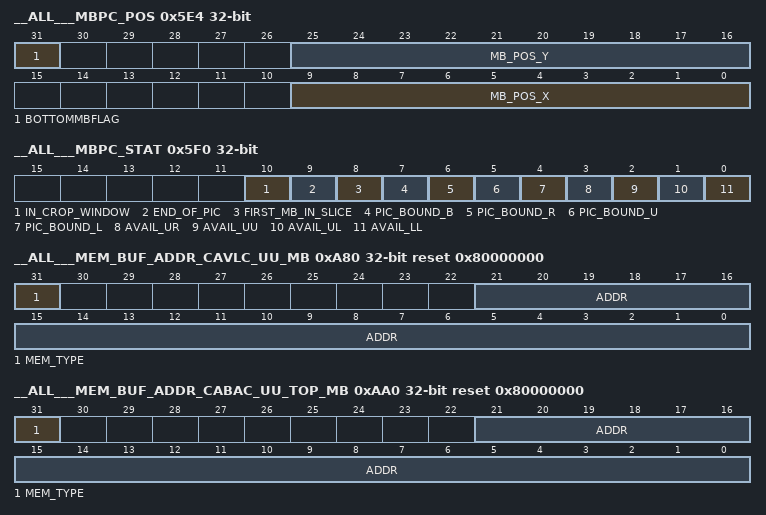
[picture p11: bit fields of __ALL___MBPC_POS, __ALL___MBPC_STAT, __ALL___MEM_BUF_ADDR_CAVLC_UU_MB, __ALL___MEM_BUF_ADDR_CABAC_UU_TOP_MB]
0x5E4 __ALL___MBPC_POS rw — FE MBPC Position
  [31] BOTTOMMBFLAG
  [25:16] MB_POS_Y — MB Position in X direction
  [9:0] MB_POS_X — MB Position in X direction
0x5E8 __ALL___MBPC_PMC ro — FE MBPC MB count in picture
  [27:0] PIC_MB_COUNT — Picture level MB Count
0x5EC __ALL___MBPC_SMC ro — FE MBPC MB count in slice
  [27:0] SLICE_MB_COUNT — Slice level MB Count
0x5F0 __ALL___MBPC_STAT — FE MBPC Status
  [10] IN_CROP_WINDOW rw — In crop window flag(for SVC)
  [9] END_OF_PIC rw — End of picture flag
  [8] FIRST_MB_IN_SLICE rw — First mb in slice flag
  [7] PIC_BOUND_B rw — Picture boundary bottom
  [6] PIC_BOUND_R rw — Picture boundary right
  [5] PIC_BOUND_U rw — Picture boundary top
  [4] PIC_BOUND_L rw — Picture boundary left
  [3] AVAIL_UR rw — UR neigbhor available
  [2] AVAIL_UU rw — UU neigbhor available
  [1] AVAIL_UL rw — UL neigbhor available
  [0] AVAIL_LL rw — LL neigbhor available
0xA00 __ALL___SL2_BUF_ADDR_BITSTRM — Bitstream SL2 Buffer Base Address
  [21:0] ADDR rw — Base address of bit stream buffer in SL2 (128 bit aligned); bits[3:0] is hardwired to 0
0xA04 __ALL___SL2_BUF_ADDR_PICREFFRAMEINFO — picRefFrameInfo SL2 Base Address
  [21:0] ADDR rw — Base Address of picRefFrameInfo in SL2 (128 bit aligned); bits[3:0] is hardwired to 0
0xA08 __ALL___SL2_BUF_ADDR_COLREFFRAMEINFO — colRefFrameInfo SL2 Base Address
  [21:0] ADDR rw — Base Address of co-located reference frame info in SL2 (128 bit aligned); bits[3:0] is hardwired to 0
0xA0C __ALL___SL2_BUF_ADDR_SLICEINFO — sliceInfo SL2 Base Address
  [21:0] ADDR rw — Base Address of sliceInfo in SL2 (128 bit aligned); bits[3:0] is hardwired to 0
0xA10 __ALL___SL2_BUF_ADDR_SLICEEXPWEIGHTTABLE — sliceExpWeightTable SL2 Base Address
  [21:0] ADDR rw — Base Address of sliceExpWeightTable in SL2 (128 bit aligned; bits[3:0] hardwired to 0
0xA14 __ALL___SL2_BUF_ADDR_SLICERPL — sliceRPL SL2 Base Address
  [21:0] ADDR rw — Base Address of sliceRPL in SL2 (128 bit aligned; bits[3:0] hardwired to 0
0xA18 __ALL___SL2_BUF_ADDR_BIN0 — Bin Stream 0 SL2 Buffer base address
  [21:0] ADDR rw — Base Address of Bin stream 0 in SL2 (128 bit aligned; bits[3:0] hardwired to 0
0xA1C __ALL___SL2_BUF_ADDR_BIN1 — Bin Stream 1 SL2 Buffer base address
  [21:0] ADDR rw — Base Address of Bin stream 1 in SL2 (128 bit aligned; bits[3:0] hardwired to 0
0xA20 __ALL___SL2_BUF_ADDR_BIN2 — Bin stream 2 SL2 Buffer base address
  [21:0] ADDR rw — Base Address of Bin stream 2 in SL2 (128 bit aligned; bits[3:0] hardwired to 0
0xA24 __ALL___SL2_BUF_ADDR_BIN3 — Bin stream 3 SL2 Buffer base address
  [21:0] ADDR rw — Base Address of Bin stream 3 in SL2 (128 bit aligned; bits[3:0] hardwired to 0
0xA28 __ALL___SL2_BUF_ADDR_COL_MBHDRINFO_TOP — Co-located Top MBHrdrInfo SL2 Base Address
  [21:0] ADDR rw — Base Address of Co-located MBHdrInfo in SL2 (128 bit aligned; bits[3:0] hardwired to 0
0xA2C __ALL___SL2_BUF_ADDR_COL_MBMVINFO_TOP — Co-located Top MBMVInfo SL2 Buffer Base Address
  [21:0] ADDR rw — Base Address of Co-located MBMVInfo in SL2 (128 bit aligned; bits[3:0] hardwired to 0
0xA30 __ALL___SL2_BUF_ADDR_COL_MBHDRINFO_BOT — Co-located Bottom MBHrdrInfo SL2 Base Address
  fields as __ALL___SL2_BUF_ADDR_COL_MBHDRINFO_TOP
0xA34 __ALL___SL2_BUF_ADDR_COL_MBMVINFO_BOT — Co-located Bottom MBMVInfo SL2 Buffer Base Address
  fields as __ALL___SL2_BUF_ADDR_COL_MBMVINFO_TOP
0xA38 __ALL___SL2_BUF_ADDR_MBHDRINFO_TOP — Current Top MBHrdrInfo SL2 Base Address
  [21:0] ADDR rw — Base Address of Current MBHdrInfo in SL2 (128 bit aligned; bits[3:0] hardwired to 0
0xA3C __ALL___SL2_BUF_ADDR_MBMVINFO_TOP — Current Top MBMVInfo SL2 Buffer Base Address
  [21:0] ADDR rw — Base Address of Current MBMVInfo in SL2 (128 bit aligned; bits[3:0] hardwired to 0
0xA40 __ALL___SL2_BUF_ADDR_MBHDRINFO_BOT — Current Bottom MBHrdrInfo SL2 Base Address
  fields as __ALL___SL2_BUF_ADDR_MBHDRINFO_TOP
0xA44 __ALL___SL2_BUF_ADDR_MBMVINFO_BOT — Current Bottom MBMVInfo SL2 Buffer Base Address
  fields as __ALL___SL2_BUF_ADDR_MBMVINFO_TOP
0xA48 __ALL___SL2_BUF_ADDR_RESIDUAL — Residual SL2 Base Address
  [21:0] ADDR rw — Base Address of Residual in SL2 (128 bit aligned; bits[3:0] hardwired to 0
0xA4C __ALL___SL2_BUF_ADDR_NF1 — NF1 SL2 Base Address
  [21:0] ADDR rw — Base Address of NF1 in SL2 (128 bit aligned; bits[3:0] hardwired to 0
0xA50 __ALL___SL2_BUF_ADDR_SVC_SLICEINFO — SVC SliceInfo Extension SL2 Base Address
  [21:0] ADDR rw — Base Address of SVC SliceInfo Extension in SL2 (128 bit aligned; bits[3:0] hardwired to 0
0xA54 __ALL___SL2_BUF_ADDR_SVC_REMBINFO — SVC Reference Layer ECD MBInfo SL2 Base Address
  [21:0] ADDR rw — Base Address of SVC Reference Layer ECD MBInfo in SL2 (128 bit aligned; bits[3:0] hardwired to 0
0xA58 __ALL___SL2_BUF_ADDR_SVC_REMBMVINFO — SVC Reference Layer ECD MBMVInfo SL2 Base Address
  [21:0] ADDR rw — Base Address of SVC Reference Layer ECD MBMVInfo in SL2 (128 bit aligned; bits[3:0] hardwired to 0
0xA60 __ALL___SL2_BUF_ADDR_BE_UU_TOP_MB — Upper Top MB SL2 Buffer Base Address for BE neighouring MB data. This register is also used as the base address for TOP_NEIGHB_MVDATA SL2 buffer ( controlled through TOP_NEIGHB_MVDATA SL2BC ), in encode.
  [21:0] ADDR rw — Base Address for Upper MB Row, Top MB in the Pair in SL2 (128 bit aligned; bits[3:0] hardwired to 0
0xA64 __ALL___SL2_BUF_ADDR_BE_UU_BOT_MB — Upper Bottom MB SL2 Buffer Base Address for BE neighbouring MB data
  [21:0] ADDR rw — Base Address for Upper MB Row, Bottom MB in the Pair in SL2 (128 bit aligned; bits[3:0] hardwired to 0
0xA80 __ALL___MEM_BUF_ADDR_CAVLC_UU_MB reset 0x80000000 — CAVLC Neighbouring MB Buffer Base Address in internal memory
  [31] MEM_TYPE rw — Specifies whether buffer is in SL2 or internal memory 0 : SL2, 1 : Internal memory
  [21:0] ADDR rw — Base Address for Neighbouring MB data for CAVLC If MEM_TYPE == 0, address in SL2 (128 bit aligned) specified; bits[3:0] hardwired to 0 If MEM_TYPE == 1, address in internal memory (128 bit aligned) specified;bits[3:0] hardwired to 0; bits [22:15] unused.
0xAA0 __ALL___MEM_BUF_ADDR_CABAC_UU_TOP_MB reset 0x80000000 — Upper Top MB Buffer Base Address for CABAC neighouring MB data in internal memory; used in CABAC encode
  fields as __ALL___MEM_BUF_ADDR_CABAC_UU_TOP_MB
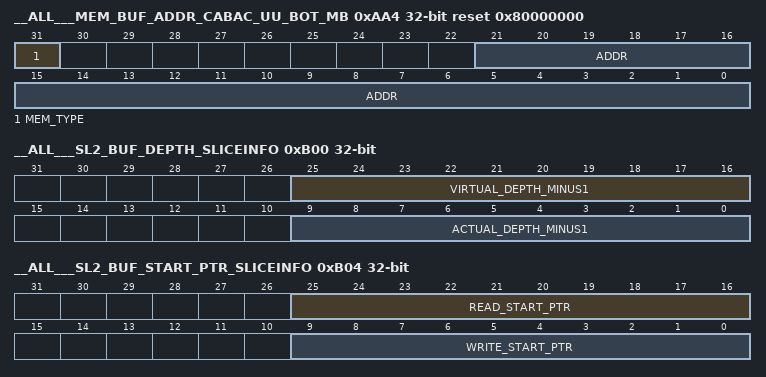
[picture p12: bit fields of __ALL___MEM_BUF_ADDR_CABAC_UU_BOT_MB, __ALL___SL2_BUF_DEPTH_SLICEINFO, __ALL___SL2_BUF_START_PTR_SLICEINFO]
0xAA4 __ALL___MEM_BUF_ADDR_CABAC_UU_BOT_MB reset 0x80000000 — Upper Top MB Buffer Base Address for CABAC neighouring MB data in internal memory; used in CABAC decode
  fields as __ALL___MEM_BUF_ADDR_CABAC_UU_BOT_MB
0xB00 __ALL___SL2_BUF_DEPTH_SLICEINFO — Buffer Control Parameters for sliceInfo Note : 1. In decode, in CABAC N MB decoupled mode, this register defines the parameters for the sliceInfo SL2BC between FE and BE (input to BE from FE) 2. In decode, in frame decoupled mode and CAVLC mode, this register defines the parameters for the sliceInfo SL2BC between the BE and the ROP (output from BE to ROP) 3. In encode, this register defines the parameters for the sliceInfo SL2BC between ROP and BE (input to BE from ROP)
  fields as __ALL___SL2_BUF_DEPTH_SLICEINFO
0xB04 __ALL___SL2_BUF_START_PTR_SLICEINFO — Buffer Control Start Pointers for sliceInfo Note : 1. In decode, in CABAC N MB decoupled mode, this register defines the read and write startpointers for the sliceInfo SL2BC between FE and BE (input to BE from FE) 2. In decode, in frame decoupled mode and CAVLC mode, this register defines the write start pointer for the sliceInfo SL2BC between the BE and the ROP (output from BE to ROP) 3. In encode, this register defines the read and write start pointers for the sliceInfo SL2BC between ROP and BE (input to BE from ROP)
  [25:16] READ_START_PTR rw — BC Start Value for Read Pointer
  [9:0] WRITE_START_PTR rw — BC Start Value for Write Pointer
